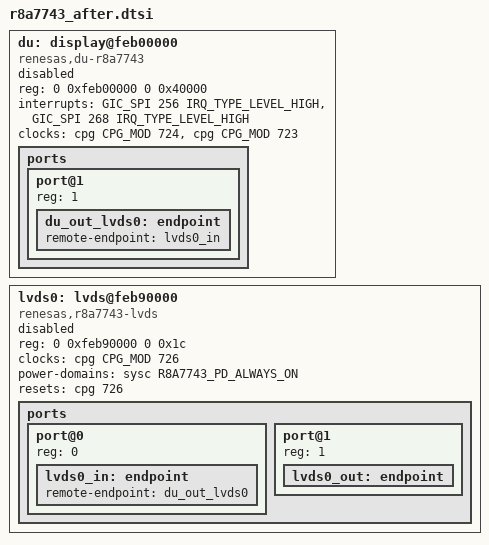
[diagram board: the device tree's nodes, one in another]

		du: display@feb00000 {
			compatible = "renesas,du-r8a7743";
			reg = <0 0xfeb00000 0 0x40000>;
			interrupts = <GIC_SPI 256 IRQ_TYPE_LEVEL_HIGH>,
				     <GIC_SPI 268 IRQ_TYPE_LEVEL_HIGH>;
			clocks = <&cpg CPG_MOD 724>,
				 <&cpg CPG_MOD 723>;
			clock-names = "du.0", "du.1";
			status = "disabled";

			ports {
				#address-cells = <1>;
				port@1 {
					reg = <1>;
					du_out_lvds0: endpoint {
						remote-endpoint = <&lvds0_in>;
					};
				};
			};
		};

		lvds0: lvds@feb90000 {
			compatible = "renesas,r8a7743-lvds";
			reg = <0 0xfeb90000 0 0x1c>;
			clocks = <&cpg CPG_MOD 726>;
			power-domains = <&sysc R8A7743_PD_ALWAYS_ON>;
			resets = <&cpg 726>;
			status = "disabled";

			ports {
				#address-cells = <1>;
				#size-cells = <0>;

				port@0 {
					reg = <0>;
					lvds0_in: endpoint {
						remote-endpoint = <&du_out_lvds0>;
					};
				};
				port@1 {
					reg = <1>;
					lvds0_out: endpoint {
					};
				};
			};
		};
